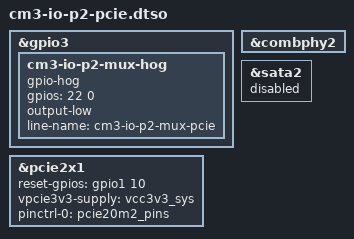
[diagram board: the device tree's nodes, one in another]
// SPDX-License-Identifier: GPL-2.0

/dts-v1/;
/plugin/;

/ {
	fragment@0 {
		target = <&gpio3>;
		__overlay__ {
			cm3-io-p2-mux-hog {
				gpio-hog;
				gpios = <22 0>;
				output-low;
				line-name = "cm3-io-p2-mux-pcie";
			};
		};
	};

	fragment@1 {
		target = <&combphy2>;
		__overlay__ {
			status = "okay";
		};
	};

	fragment@2 {
		target = <&sata2>;
		__overlay__ {
			status = "disabled";
		};
	};

	fragment@3 {
		target = <&pcie2x1>;
		__overlay__ {
			status = "okay";
			reset-gpios = <&gpio1 10 0>;
			vpcie3v3-supply = <&vcc3v3_sys>;
			pinctrl-names = "default";
			pinctrl-0 = <&pcie20m2_pins>;
		};
	};
};
